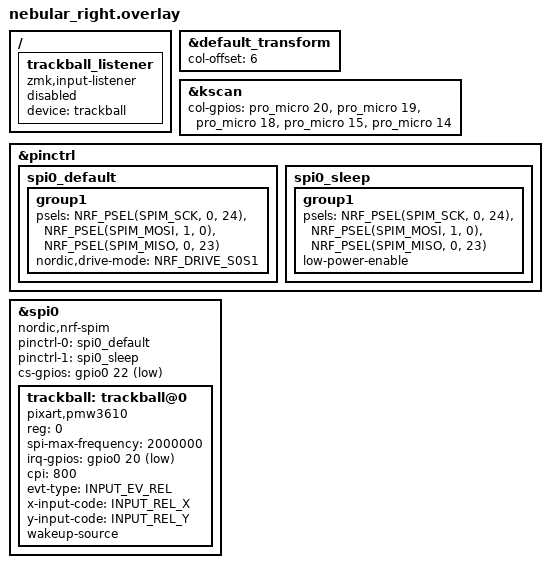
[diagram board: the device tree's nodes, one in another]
#include "nebular.dtsi"
#include <zephyr/dt-bindings/input/input-event-codes.h>

/* nice!nano v2 pin map – adjust if you wired differently                *
 *  SCK  = P0.24 (D5)                                                    *
 *  SDIO = P1.00 (D6) – shared MOSI/MISO                                 *
 *  CS   = P0.22 (D4)                                                    *
 *  MOT  = P0.20 (D3) – motion interrupt                                 */

&default_transform {
    // Set this to the number of columns on the left side.
    col-offset = <6>;
};

&kscan {
    // Replace these comments with the GPIO pins in the matrix for the right side.
    // See https://zmk.dev/docs/development/hardware-integration/new-shield#shield-overlays
    col-gpios
        = <&pro_micro 20 GPIO_ACTIVE_HIGH>
        , <&pro_micro 19 GPIO_ACTIVE_HIGH>
        , <&pro_micro 18 GPIO_ACTIVE_HIGH>
        , <&pro_micro 15 GPIO_ACTIVE_HIGH>
        , <&pro_micro 14 GPIO_ACTIVE_HIGH>
        ;
};

&pinctrl {
    spi0_default: spi0_default {
        group1 {
            psels = <NRF_PSEL(SPIM_SCK, 0, 24)>,
                    <NRF_PSEL(SPIM_MOSI, 1, 0)>,
                    <NRF_PSEL(SPIM_MISO, 0, 23)>; /* dummy MISO */
            nordic,drive-mode = <NRF_DRIVE_S0S1>;
        };
    };
    spi0_sleep: spi0_sleep {
        group1 {
            psels = <NRF_PSEL(SPIM_SCK, 0, 24)>,
                    <NRF_PSEL(SPIM_MOSI, 1, 0)>,
                    <NRF_PSEL(SPIM_MISO, 0, 23)>;
            low-power-enable;
        };
    };
};

&spi0 {
    compatible = "nordic,nrf-spim";
    status = "okay";
    pinctrl-0 = <&spi0_default>;
    pinctrl-1 = <&spi0_sleep>;
    pinctrl-names = "default", "sleep";
    cs-gpios = <&gpio0 22 GPIO_ACTIVE_LOW>;

    trackball: trackball@0 {
        compatible = "pixart,pmw3610";
        reg = <0>;
        spi-max-frequency = <2000000>;
        irq-gpios = <&gpio0 20 (GPIO_ACTIVE_LOW | GPIO_PULL_UP)>;
        cpi = <800>;          /* adjust sensitivity */
        /* Optional axis tweaks:
         * swap-xy; invert-x; invert-y; */

        evt-type      = <INPUT_EV_REL>;
        x-input-code  = <INPUT_REL_X>;
        y-input-code  = <INPUT_REL_Y>;

        wakeup-source;
        status = "okay";
    };
};

/* listener node kept disabled here; enabled on central side */
/ {
    trackball_listener: trackball_listener {
        compatible = "zmk,input-listener";
        device = <&trackball>;
        status = "disabled";
    };
};
